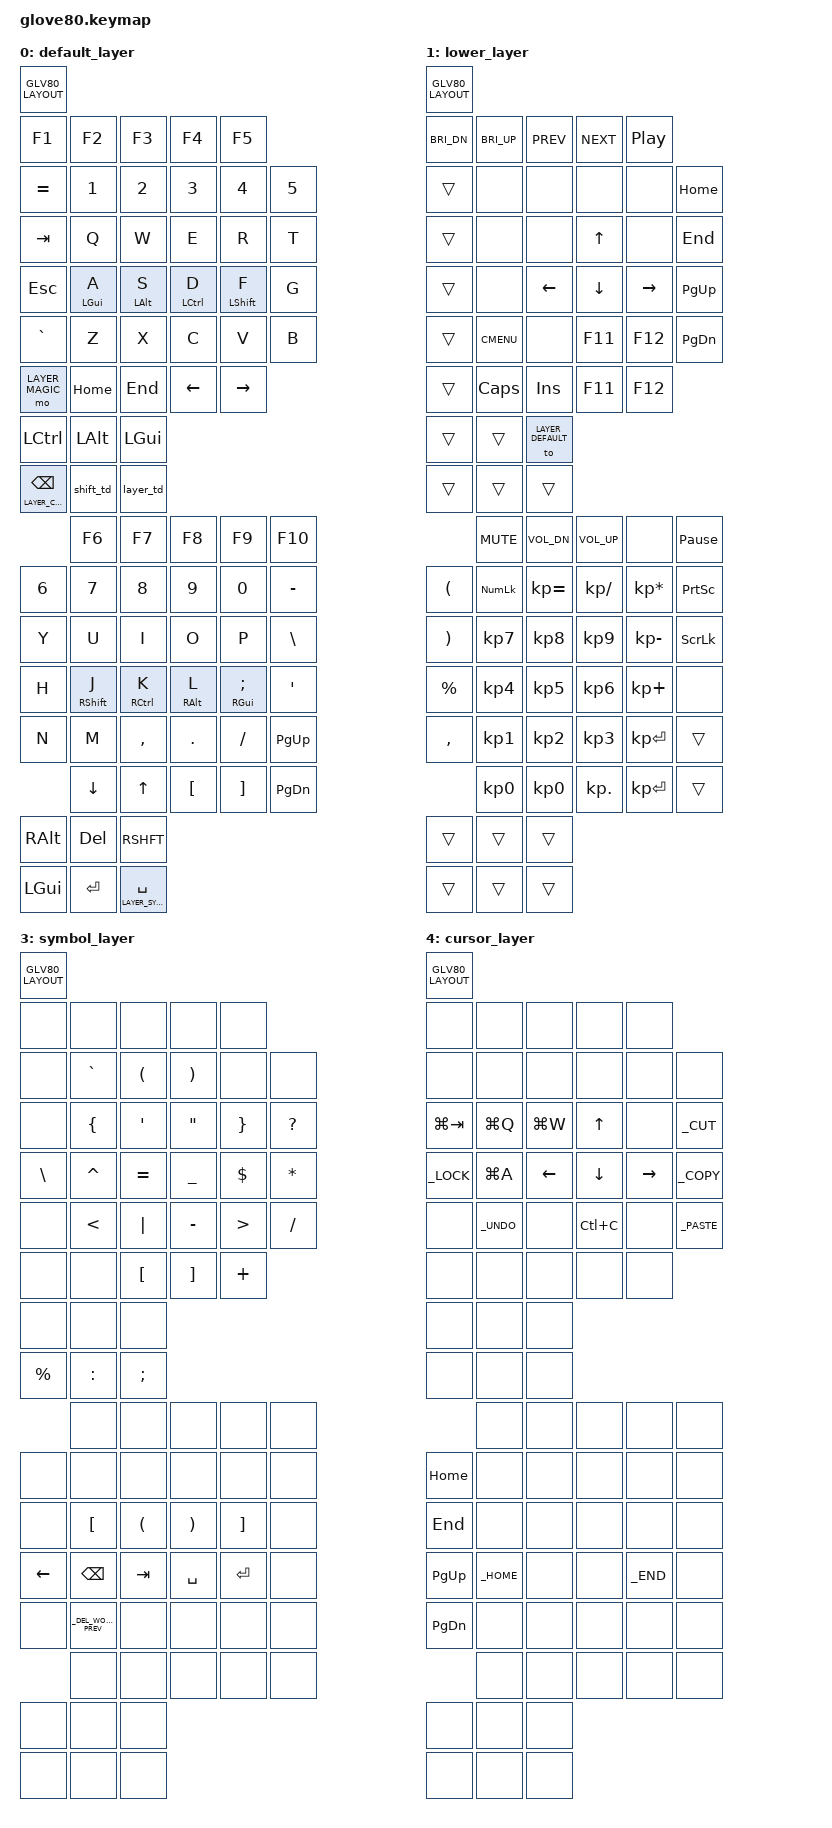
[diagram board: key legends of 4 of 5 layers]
#include <behaviors.dtsi>
#include <dt-bindings/zmk/keys.h>
#include <dt-bindings/zmk/bt.h>
#include <dt-bindings/zmk/ext_power.h>
#include <dt-bindings/zmk/outputs.h>
#include <dt-bindings/zmk/rgb.h>

#include "zmk-helpers/helper.h"
#include "zmk-helpers/key-labels/glove80.h"

#define KEYS_T RH0 RH1 RH2 RH3 RH4 RH5 LH0 LH1 LH2 LH3 LH4 LH5
#define KEYS_L LC1 LC2 LC3 LC4 LC5 LN0 LN1 LN2 LN3 LN4 LN5 LM0 LM1 LM2 LM3 LM4 LM5 LB0 LB1 LB2 LB3 LB4 LB5 LF1 LF2 LF3 LF4 LF5 LT0 LT1 LT2 LT3 LT4 LT5 
#define HRM_L LM1 LM2 LM3 LM4
#define KEYS_R RC1 RC2 RC3 RC4 RC5 RN0 RN1 RN2 RN3 RN4 RN5 RM0 RM1 RM2 RM3 RM4 RM5 RB0 RB1 RB2 RB3 RB4 RB5 RF1 RF2 RF3 RF4 RF5 RT0 RT1 RT2 RT3 RT4 RT5
#define HRM_R RM1 RM2 RM3 RM4

#include "helper.dtsi"
#include "combos.dtsi"
#include "hrm.dtsi"

#define LAYER_DEFAULT 0
#define LAYER_LOWER 1
#define LAYER_MAGIC 2
#define LAYER_SYMBOL 3
#define LAYER_CURSOR 4

/ {
    behaviors {
        // For the "layer" key, it'd nice to be able to use it as either a shift or a toggle.
        // Configure it as a tap dance, so the first tap (or hold) is a &mo and the second tap is a &to
        layer_td: tap_dance_0 {
            compatible = "zmk,behavior-tap-dance";
            #binding-cells = <0>;
            tapping-term-ms = <200>;
            bindings = <&mo LAYER_LOWER>, <&to LAYER_LOWER>;
        };

        shift_td: tap_dance_shift {
            compatible = "zmk,behavior-tap-dance";
            #binding-cells = <0>;
            tapping-term-ms = <200>;
            bindings = <&kp LSHFT>, <&kp CAPS>;
        };
    };

    macros {
        bt_0: bt_profile_macro_0 {
            compatible = "zmk,behavior-macro";
            #binding-cells = <0>;
            bindings
                = <&out OUT_BLE>,
                  <&bt BT_SEL 0>;
        };

        bt_1: bt_profile_macro_1 {
            compatible = "zmk,behavior-macro";
            #binding-cells = <0>;
            bindings
                = <&out OUT_BLE>,
                  <&bt BT_SEL 1>;
        };

        bt_2: bt_profile_macro_2 {
            compatible = "zmk,behavior-macro";
            #binding-cells = <0>;
            bindings
                = <&out OUT_BLE>,
                  <&bt BT_SEL 2>;
        };

        bt_3: bt_profile_macro_3 {
            compatible = "zmk,behavior-macro";
            #binding-cells = <0>;
            bindings
                = <&out OUT_BLE>,
                  <&bt BT_SEL 3>;
        };
    };

    keymap {
        compatible = "zmk,keymap";

        default_layer {
            bindings = <GLV80_LAYOUT(
// ------------------------------------------------------------------------- ,
   &kp F1          &kp F2      &kp F3      &kp F4       &kp F5               ,
   &kp EQUAL       &kp N1      &kp N2      &kp N3       &kp N4        &kp N5 ,
   &kp TAB         &kp Q       &kp W       &kp E        &kp R         &kp T  ,
   &kp ESC         &hml LGUI A &hml LALT S &hml LCTRL D &hmls LSHFT F &kp G  ,
   &kp GRAVE       &kp Z       &kp X       &kp C        &kp V         &kp B  ,
   &mo LAYER_MAGIC &kp HOME    &kp END     &kp LEFT     &kp RIGHT            ,
// ------------------------------------------------------------------------- ,
   &kp LCTRL             &kp LALT  &kp LGUI                                  ,
   &lt LAYER_CURSOR BSPC &shift_td &layer_td                                 ,
// ------------------------------------------------------------------------- ,
          &kp F6        &kp F7       &kp F8      &kp F9         &kp F10      ,
   &kp N6 &kp N7        &kp N8       &kp N9      &kp N0         &kp MINUS    ,
   &kp Y  &kp U         &kp I        &kp O       &kp P          &kp BSLH     ,
   &kp H  &hmrs RSHFT J &hmr RCTRL K &hmr RALT L &hmr RGUI SEMI &kp SQT      ,
   &kp N  &kp M         &kp COMMA    &kp DOT     &kp FSLH       &kp PG_UP    ,
          &kp DOWN      &kp UP       &kp LBKT    &kp RBKT       &kp PG_DN    ,
// ------------------------------------------------------------------------- ,
   &kp RALT &kp DEL &RSHFT                                                   ,
   &kp LGUI &kp RET &lt LAYER_SYMBOL SPACE                                   ,
)>;
        };

        lower_layer {
            bindings = <GLV80_LAYOUT(
// ------------------------------------------------------------------------------- ,
   &kp C_BRI_DN &kp C_BRI_UP &kp C_PREV &kp C_NEXT &kp C_PP                        ,
   &trans       &none        &none      &none      &none     &kp HOME              ,
   &trans       &none        &none      &kp UP     &none     &kp END               ,
   &trans       &none        &kp LEFT   &kp DOWN   &kp RIGHT &kp PG_UP             ,
   &trans       &kp K_CMENU  &none      &kp F11    &kp F12   &kp PG_DN             ,
   &trans       &kp CAPS     &kp INS    &kp F11    &kp F12                         ,
// ------------------------------------------------------------------------------- ,
   &trans &trans &to LAYER_DEFAULT                                                 ,
   &trans &trans &trans                                                            ,
// ------------------------------------------------------------------------------- ,
             &kp C_MUTE &kp C_VOL_DN &kp C_VOL_UP  &none           &kp PAUSE_BREAK ,
   &kp LPAR  &kp KP_NUM &kp KP_EQUAL &kp KP_DIVIDE &kp KP_MULTIPLY &kp PSCRN       ,
   &kp RPAR  &kp KP_N7  &kp KP_N8    &kp KP_N9     &kp KP_MINUS    &kp SLCK        ,
   &kp PRCNT &kp KP_N4  &kp KP_N5    &kp KP_N6     &kp KP_PLUS     &none           ,
   &kp COMMA &kp KP_N1  &kp KP_N2    &kp KP_N3     &kp KP_ENTER    &trans          ,
             &kp KP_N0  &kp KP_N0    &kp KP_DOT    &kp KP_ENTER    &trans          ,
// ------------------------------------------------------------------------------- ,
   &trans &trans &trans                                                            ,
   &trans &trans &trans                                                            ,
)>;
        };

        magic_layer {
            bindings = <
&bt BT_CLR &none &none &none &none &none &none &none &none &none
&none &none &none &none &none &none &none &none &none &none &none &none
&none &rgb_ug RGB_SPI &rgb_ug RGB_SAI &rgb_ug RGB_HUI &rgb_ug RGB_BRI &rgb_ug RGB_TOG &none &none &none &none &none &none
&bootloader &rgb_ug RGB_SPD &rgb_ug RGB_SAD &rgb_ug RGB_HUD &rgb_ug RGB_BRD &rgb_ug RGB_EFF &none &none &none &none &none &bootloader
&sys_reset &none &none &none &none &none &bt_2 &bt_3 &none &none &none &none &none &none &none &none &none &sys_reset
&none &none &none &none &none &bt_0 &bt_1 &out OUT_USB &none &none &none &none &none &none &none &none
            >;
        };

        symbol_layer {
            bindings = <GLV80_LAYOUT(
// ----------------------------------------------------------------------------- ,
   &none    &none     &none            &none             &none                   ,
   &none    &kp GRAVE &kp LPAR         &kp RPAR          &none      &none        ,
   &none    &kp LBRC  &kp SINGLE_QUOTE &kp DOUBLE_QUOTES &kp RBRC   &kp QUESTION ,
   &kp BSLH &kp CARET &kp EQUAL        &kp UNDERSCORE    &kp DOLLAR &kp ASTRK    ,
   &none    &kp LT    &kp PIPE         &kp MINUS         &kp GT     &kp SLASH    ,
   &none    &none     &kp LBKT         &kp RBKT          &kp PLUS                ,
// ----------------------------------------------------------------------------- ,
   &none       &none     &none                                                   ,
   &kp PERCENT &kp COLON &kp SEMI                                                ,
// ----------------------------------------------------------------------------- ,
            &none              &none    &none     &none    &none                 ,
   &none    &none              &none    &none     &none    &none                 ,
   &none    &kp LBKT           &kp LPAR &kp RPAR  &kp RBKT &none                 ,
   &kp LEFT &kp BSPC           &kp TAB  &kp SPACE &kp RET  &none                 ,
   &none    &kp _DEL_WORD_PREV &none    &none     &none    &none                 ,
            &none              &none    &none     &none    &none                 ,
// ----------------------------------------------------------------------------- ,
   &none &none &none                                                             ,
   &none &none &none                                                             ,
)>;
        };

        cursor_layer {
			bindings = <GLV80_LAYOUT(
// -------------------------------------------------------------- ,
   &none       &none     &none     &none     &none                ,
   &none       &none     &none     &none     &none     &none      ,
   &kp LG(TAB) &kp LG(Q) &kp LG(W) &kp UP    &none     &kp _CUT   ,
   &kp _LOCK   &kp LG(A) &kp LEFT  &kp DOWN  &kp RIGHT &kp _COPY  ,
   &none       &kp _UNDO &none     &kp LC(C) &none     &kp _PASTE ,
   &none       &none     &none     &none     &none                ,
// -------------------------------------------------------------- ,
   &none &none &none                                              ,
   &none &none &none                                              ,
// -------------------------------------------------------------- ,
             &none     &none &none &none    &none                 ,
   &kp HOME  &none     &none &none &none    &none                 ,
   &kp END   &none     &none &none &none    &none                 ,
   &kp PG_UP &kp _HOME &none &none &kp _END &none                 ,
   &kp PG_DN &none     &none &none &none    &none                 ,
             &none     &none &none &none    &none                 ,
// -------------------------------------------------------------- ,
   &none &none &none                                              ,
   &none &none &none                                              ,
)>;
        };
    };
};
